# nrf9230_enga_cellcore register map
Vendor: Nordic Semiconductor; Series: nRF92; File version: 1
CPU: CM33 r0p4, little endian, MPU, FPU, 3 interrupt priority bits, 480 interrupts, 8 SAU regions
Registers are 32-bit, read-write, reset 0x0 unless marked. A register's access mark holds for its fields unless they carry their own. Offsets are from the block's base; [hi:lo] are bit positions; {n}, {i} and the like mark numbered series.

## RAMC00_NS — RAM Controller 0
Base 0x44006000
Same registers: RAMC00_S 0x54006000
0x500 WAITSTATES — Waitstates for read operations.
  [0] WAITSTATES — Number of waitstates for a read from the RAM.
0x600 SECBASE — Base address for secure access area.
  [31:0] ADDR — Base address
0x604 SECENABLE — Enable secure access restrictions.
  [0] ENABLE — Enable secure access restrictions
    0=Disable (Secure access restrictions disabled); 1=Enable (Secure access restrictions enabled)

## TRACEDELAYREG_NS — Trace delay register 0
Base 0x4400B000
Same registers: TRACEDELAYREG_S 0x5400B000
0x504 DELAYREGCONFIG — Configuration register for DELAYREG delay
  [4:0] DELAYREGCONFIG — Register write delay, configurable between 0 and 31 clock cycles. Delay between apbPEnable and apbPReady is adjusted to the configured value, except for the small values, when minimum interconnect delay exist.
0x600 DELAYREG wo — Dummy register with adjustable write delay. Occupies 0x100 address range i.e. 256bytes. This space emulates the extended stimulus port area of ARM Coresight STM.
  [31:0] DELAYREG — Dummy register with adjustable write delay

## PCGCS0_NS — PCGCSlave 0
Base 0x4400C000
Same registers: PCGCS1_NS 0x44018000, PCGCS2_NS 0x44027000, PCGCS3_NS 0x44036000, PCGCS0_S 0x5400C000, PCGCS1_S 0x54018000, PCGCS2_S 0x54027000, PCGCS3_S 0x54036000
{0xC00+4i} PENALTY[{i}] (i=0..1) reset 0xFFFFFFFC — Description collection: Penalty level for power/clock pair n. When FULL_PCP_ZERO feature is not supported, PENALTY[0] address overlaps the PENALTY0 address and register description for PENALTY[0] is not valid.
  [1:0] PENALTY — Penalty level
0xC00 PENALTY0 (alternate view of PENALTY[*]) — Penalty level for power/clock pair 0. The register description is valid only when FULL_PCP_ZERO feature is not supported
  [1:0] PENALTY ro — Penalty level
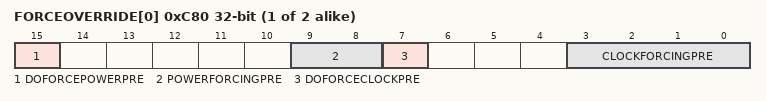
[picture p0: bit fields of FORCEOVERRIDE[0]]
{0xC80+4i} FORCEOVERRIDE[{i}] (i=0..1) — Description collection: Force override of power/clock pair n.
  [15] DOFORCEPOWERPRE, [9:8] POWERFORCINGPRE, [7] DOFORCECLOCKPRE, [3:0] CLOCKFORCINGPRE

## CELLCOREHSPDCTRL_NS — Cellular core HSPD FSM control
Base 0x5400C500; alternate view of PCGCS0_S
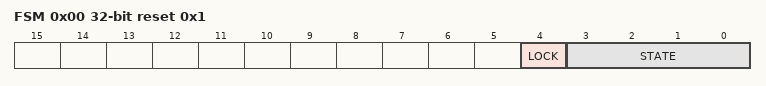
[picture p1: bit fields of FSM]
0x00 FSM reset 0x1 — High speed power domain finite state machine control
  [4] LOCK — Lock the state of HSFSM.
    0=UNLOCKED (FSM not locked.); 1=LOCKED (FSM locked.)
  [3:0] STATE — HSFSM state
    0=HSPD_AFTER_RESET (PD_CORE_ACT powered. State after CPUCONF reset. Next state NORMAL_ON.); 1=HSPD_RESET (PD_CORE_ACT powered. State after power domain reset. Next state NORMAL_ON.); 2=RST_WARNING_ACTIVE (PD_CORE_ACT powered. PD_CORE_ACT powered. Resetwarning coming from GRC.); 3=CPU_RST_REQUEST (PD_CORE_ACT powered. CPU requesting reset from GRC.); 4=WDT0_RST_REQUEST (PD_CORE_ACT powered. WDT0 requesting reset from GRC.); 5=WDT1_RST_REQUEST (PD_CORE_ACT powered. WDT1 requesting reset from GRC.); 6=LOCKUP_RST_REQUEST (PD_CORE_ACT powered. CPU lockup requesting reset from GRC.); 7=DEEPSLEEP (PD_CORE_ACT powering down. CPU in deepsleep.); 8=BRIDGE_SERVICE (PD_CORE_ACT powered. CPU is not running, AXI activity monitored.); 9=DEEPSLEEP_REQUEST (PD_CORE_ACT powered. Preparing to go DEEPSLEEP.); 10=LIGHTSLEEP (PD_CORE_ACT powered. CPU in lightsleep and clocks not requested.); 11=NORMAL_ON (PD_CORE_ACT powered. Normal operating state. CPU on.); 12=CPU_NOT_STARTED (PD_CORE_ACT powered.)

## PCGCM0_NS — PCGC Master 0
Base 0x4400D000
Same registers: PCGCM1_NS 0x44019000, PCGCM3_NS 0x44037000, PCGCM0_S 0x5400D000, PCGCM1_S 0x54019000, PCGCM3_S 0x54037000
{0xE0+4i} SETPWRCONTHRESHOLDBASE[{i}] (i=0..2) — Description collection: Set power consumption threshold base for power source / regulator n
  [3:0] SETPWRCONTHRESHOLDBASE
0xC00 UNLOCKBACKDOORS
  [15:0] UNLOCKBACKDOORS — Write: 0x00009375 to lock/unlock backdoors Read: 0x00000001 if backdoors is enabled Read: 0x00000000 if backdoors is disabled
0xC04 ENABLEPOWERREGFORCE
  [2:0] ENABLEPOWERREGFORCE
0xC08 POWERREGFORCE — Force reg
  [2:0] POWERREGFORCEREG
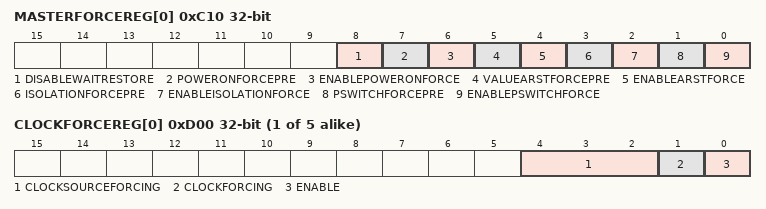
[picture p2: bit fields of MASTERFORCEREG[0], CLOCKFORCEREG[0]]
{0xC10+4i} MASTERFORCEREG[{i}] (i=0..0) — Description collection: Force reg
  [8] DISABLEWAITRESTORE — Turn off waiting for arst deactivation before retention restore
    1=Disable (Turn off waiting for arst deactivation before retention restore); 0=Enable (Wait for arst deactivation before retention restore)
  [7] POWERONFORCEPRE
  [6] ENABLEPOWERONFORCE
  [5] VALUEARSTFORCEPRE
  [4] ENABLEARSTFORCE
  [3] ISOLATIONFORCEPRE
  [2] ENABLEISOLATIONFORCE
  [1] PSWITCHFORCEPRE
  [0] ENABLEPSWITCHFORCE
{0xD00+4i} CLOCKFORCEREG[{i}] (i=0..4) — Description collection: Force clock n
  [4:2] CLOCKSOURCEFORCING
  [1] CLOCKFORCING
  [0] ENABLE — Enable clock forcing

## Notices in the file
Copyright (c) 2010 - 2024, Nordic Semiconductor ASA
All rights reserved.
Redistribution and use in source and binary forms, with or without modification,
are permitted provided that the following conditions are met:
1. Redistributions of source code must retain the above copyright notice, this
list of conditions and the following disclaimer.
2. Redistributions in binary form, except as embedded into a Nordic
Semiconductor ASA integrated circuit in a product or a software update for
such product, must reproduce the above copyright notice, this list of
conditions and the following disclaimer in the documentation and/or other
materials provided with the distribution.
3. Neither the name of Nordic Semiconductor ASA nor the names of its
contributors may be used to endorse or promote products derived from this
software without specific prior written permission.
4. This software, with or without modification, must only be used with a
Nordic Semiconductor ASA integrated circuit.
5. Any software provided in binary form under this license must not be reverse
engineered, decompiled, modified and/or disassembled.
THIS SOFTWARE IS PROVIDED BY NORDIC SEMICONDUCTOR ASA "AS IS" AND ANY EXPRESS
OR IMPLIED WARRANTIES, INCLUDING, BUT NOT LIMITED TO, THE IMPLIED WARRANTIES
OF MERCHANTABILITY, NONINFRINGEMENT, AND FITNESS FOR A PARTICULAR PURPOSE ARE
DISCLAIMED. IN NO EVENT SHALL NORDIC SEMICONDUCTOR ASA OR CONTRIBUTORS BE
LIABLE FOR ANY DIRECT, INDIRECT, INCIDENTAL, SPECIAL, EXEMPLARY, OR
CONSEQUENTIAL DAMAGES (INCLUDING, BUT NOT LIMITED TO, PROCUREMENT OF SUBSTITUTE
GOODS OR SERVICES; LOSS OF USE, DATA, OR PROFITS; OR BUSINESS INTERRUPTION)
HOWEVER CAUSED AND ON ANY THEORY OF LIABILITY, WHETHER IN CONTRACT, STRICT
LIABILITY, OR TORT (INCLUDING NEGLIGENCE OR OTHERWISE) ARISING IN ANY WAY OUT
OF THE USE OF THIS SOFTWARE, EVEN IF ADVISED OF THE POSSIBILITY OF SUCH DAMAGE.
